# f2838x_cm_cm_wd_regs register map
Vendor: Texas Instruments
Peripheral module from a debugger description file (folder C2000).
Address unit: 16 bits
Registers are 32-bit, access per field, no defined reset value unless marked. A register's access mark holds for its fields unless they carry their own. Offsets are as the file gives them; lines under a group give offsets from that group; [hi:lo] are bit positions; {n}, {i} and the like mark numbered series; 'fields as' and 'values as' point back to an identical list; <NAME> marks a mode.

## CM_WD_REGS — CM WD Registers
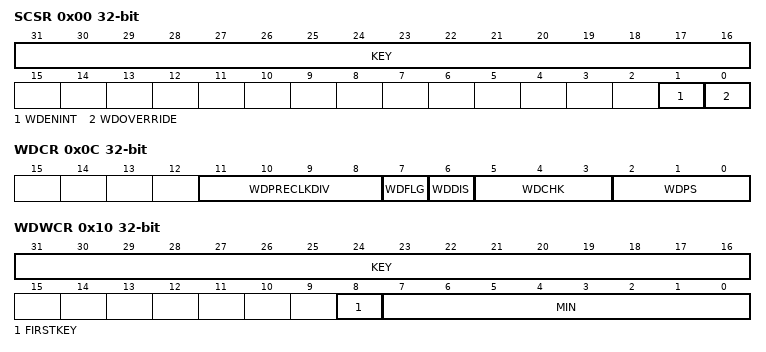
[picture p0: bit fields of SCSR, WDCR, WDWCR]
0x00 SCSR — System Control and Status Register
  [31:16] KEY rw
  [1] WDENINT ro — WD Interrupt Enable
  [0] WDOVERRIDE rw — WD Override for WDDIS bit
0x04 WDCNTR ro — Watchdog Counter Register
  [7:0] WDCNTR — WD Counter
0x08 WDKEY — Watchdog Reset Key Register
  [7:0] WDKEY rw
0x0C WDCR — Watchdog Control Register
  [11:8] WDPRECLKDIV rw — WD Pre Clock Divider
  [7] WDFLG rw — WD Reset Status Flag
  [6] WDDIS rw — WD Disable
  [5:3] WDCHK rw — WD Check Bits
  [2:0] WDPS rw — WD Clock Prescalar
0x10 WDWCR — Watchdog Windowed Control Register
  [31:16] KEY rw
  [8] FIRSTKEY ro — First Key Detect Flag
  [7:0] MIN rw — WD Min Threshold setting for Windowed Watchdog functionality
